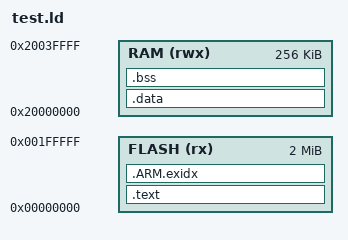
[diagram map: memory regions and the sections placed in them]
ENTRY(TestReset)
MEMORY {
    FLASH (rx) : ORIGIN = 0, LENGTH = 2M
    RAM (rwx) : ORIGIN = 0x20000000, LENGTH = 256K
}
SECTIONS {
    .text : { KEEP(*(.vectors)) *(.text*) *(.rodata*) } > FLASH
    .ARM.exidx : { *(.ARM.exidx*) } > FLASH
    .data : { *(.data*) } > RAM
    .bss (NOLOAD) : { *(.bss*) *(COMMON) } > RAM
}
